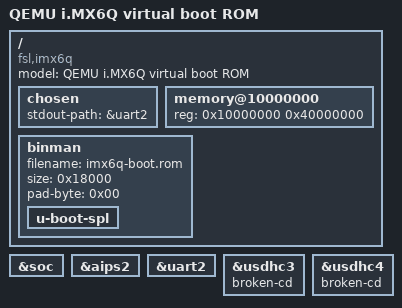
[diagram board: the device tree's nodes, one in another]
// SPDX-License-Identifier: GPL-2.0+
/*
 * Device tree of the QEMU i.MX6Q virtual boot ROM. The ROM only needs the
 * console UART and the USDHC controllers it can boot from, i.e. the ones of
 * the SD card slots of the SABRE Lite board.
 */

/dts-v1/;
#include "imx6q.dtsi"

/ {
	model = "QEMU i.MX6Q virtual boot ROM";
	compatible = "fsl,imx6q";

	chosen {
		stdout-path = &uart2;
	};

	memory@10000000 {
		device_type = "memory";
		reg = <0x10000000 0x40000000>;
	};

	/* Image for QEMU's -bios option, sized like the boot ROM region */
	binman {
		filename = "imx6q-boot.rom";
		size = <0x18000>;
		pad-byte = <0x00>;

		u-boot-spl {
		};
	};
};

&soc {
	bootph-pre-ram;
};

&aips2 {
	bootph-pre-ram;
};

&uart2 {
	bootph-pre-ram;
	status = "okay";
};

/* The ROM doesn't use card detect or write protect GPIOs */
&usdhc3 {
	bootph-pre-ram;
	broken-cd;
	status = "okay";
};

&usdhc4 {
	bootph-pre-ram;
	broken-cd;
	status = "okay";
};
